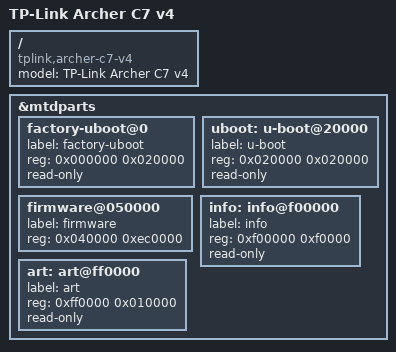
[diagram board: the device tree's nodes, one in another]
// SPDX-License-Identifier: GPL-2.0-or-later OR MIT
/dts-v1/;

#include "qca9563_tplink_archer-x7-v4-v5.dtsi"

/ {
	compatible = "tplink,archer-c7-v4", "qca,qca9563";
	model = "TP-Link Archer C7 v4";
};

&mtdparts {
	factory-uboot@0 {
		label = "factory-uboot";
		reg = <0x000000 0x020000>;
		read-only;
	};

	uboot: u-boot@20000 {
		label = "u-boot";
		reg = <0x020000 0x020000>;
		read-only;
	};

	firmware@050000 {
		label = "firmware";
		reg = <0x040000 0xec0000>;
	};

	info: info@f00000 {
		label = "info";
		reg = <0xf00000 0xf0000>;
		read-only;
	};

	art: art@ff0000 {
		label = "art";
		reg = <0xff0000 0x010000>;
		read-only;
	};
};
